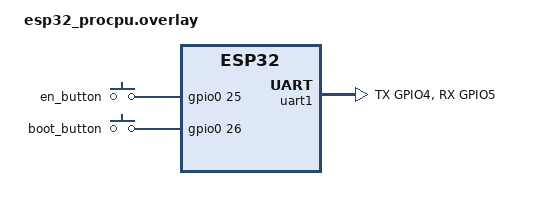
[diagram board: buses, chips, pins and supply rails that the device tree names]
/*
 * Copyright (c) 2024 Espressif Systems (Shanghai) Co., Ltd.
 *
 * SPDX-License-Identifier: Apache-2.0
 */

/ {
	aliases {
		en = &en_button;
		boot = &boot_button;
		uart = &uart1;
	};

	gpio_keys {
		compatible = "gpio-keys";
		en_button: en_button {
			gpios = <&gpio0 25 (GPIO_PULL_UP | GPIO_ACTIVE_HIGH)>;
		};
		boot_button: boot_button {
			gpios = <&gpio0 26 (GPIO_PULL_UP | GPIO_ACTIVE_HIGH)>;
		};
	};
};

&pinctrl {
	uart1_example: uart1_example {
		group1 {
			pinmux = <UART1_TX_GPIO4>;
			input-enable;
		};
		group2 {
			pinmux = <UART1_RX_GPIO5>;
			output-enable;
		};
	};
};

&uart1 {
	status = "okay";
	pinctrl-0 = <&uart1_example>;
	pinctrl-names = "default";
};
